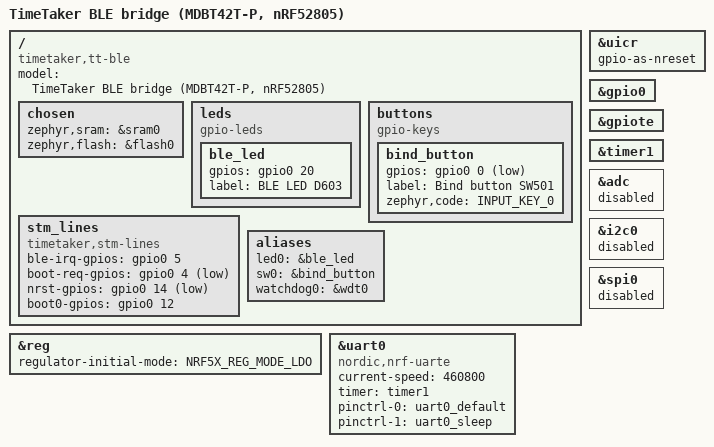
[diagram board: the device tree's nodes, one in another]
/*
 * TimeTaker BLE bridge: U501 Raytac MDBT42T-P (nRF52805) on the control
 * module. Pin map: BLE_FIRMWARE_GUIDE.md §3.2, HARDWARE_REFERENCE.md §2.6.
 *
 * Differences from nrf52dk/nrf52805, all deliberate:
 *   - LDO regulator: the module's DCC pin is not connected, DC/DC would
 *     brown the chip out.
 *   - No console: UARTE0 is the STM link (460800 8N1, no flow control).
 *   - No ADC, I2C, SPI. No DK buttons/LEDs.
 */

/dts-v1/;
#include <nordic/nrf52805_caaa.dtsi>
#include "tt_ble-pinctrl.dtsi"
#include <zephyr/dt-bindings/input/input-event-codes.h>

/ {
	model = "TimeTaker BLE bridge (MDBT42T-P, nRF52805)";
	compatible = "timetaker,tt-ble";

	chosen {
		zephyr,sram = &sram0;
		zephyr,flash = &flash0;
		/* No zephyr,console: there is no UART for it (RTT in debug builds). */
	};

	leds {
		compatible = "gpio-leds";

		/* D603 via R603 1 k to GND: active high. */
		ble_led: ble_led {
			gpios = <&gpio0 20 GPIO_ACTIVE_HIGH>;
			label = "BLE LED D603";
		};
	};

	buttons {
		compatible = "gpio-keys";

		/* SW501 to GND, R501 10 k external pull-up: no internal pull. */
		bind_button: bind_button {
			gpios = <&gpio0 0 GPIO_ACTIVE_LOW>;
			label = "Bind button SW501";
			zephyr,code = <INPUT_KEY_0>;
		};
	};

	/* The lines to the STM32 (BLE_FIRMWARE_GUIDE.md §7.3). */
	stm_lines: stm_lines {
		compatible = "timetaker,stm-lines";
		/* P0.05 -> PB5: high while a central is connected. */
		ble-irq-gpios = <&gpio0 5 GPIO_ACTIVE_HIGH>;
		/* P0.04 -> PB4: BOOT_REQ, active low (PB4 pull-up = no request). */
		boot-req-gpios = <&gpio0 4 GPIO_ACTIVE_LOW>;
		/* P0.14 -> NRST: open drain ONLY, active low. Never push-pull. */
		nrst-gpios = <&gpio0 14 (GPIO_ACTIVE_LOW | GPIO_OPEN_DRAIN)>;
		/* P0.12 -> BOOT0: never driven in v1 (R201 pull-down on the STM). */
		boot0-gpios = <&gpio0 12 GPIO_ACTIVE_HIGH>;
	};

	aliases {
		led0 = &ble_led;
		sw0 = &bind_button;
		watchdog0 = &wdt0;
	};
};

&reg {
	regulator-initial-mode = <NRF5X_REG_MODE_LDO>;
};

&uicr {
	/* P0.21 is the J501 reset pin. */
	gpio-as-nreset;
};

&gpio0 {
	status = "okay";
};

&gpiote {
	status = "okay";
};

/* TIMER1 counts UARTE RX bytes (reliable async RX without flow control).
 * TIMER0 and RTC0 belong to the BLE controller (MPSL). */
&timer1 {
	status = "okay";
};

&uart0 {
	compatible = "nordic,nrf-uarte";
	status = "okay";
	current-speed = <460800>;
	timer = <&timer1>;
	pinctrl-0 = <&uart0_default>;
	pinctrl-1 = <&uart0_sleep>;
	pinctrl-names = "default", "sleep";
};

&adc {
	status = "disabled";
};

&i2c0 {
	status = "disabled";
};

&spi0 {
	status = "disabled";
};
